# Video_Encoder register map
Vendor: Texas Instruments
Peripheral module from a debugger description file (folder omap36xx).
Registers are 32-bit, read-write, reset 0x0 unless marked. A register's access mark holds for its fields unless they carry their own. Offsets are as the file gives them; lines under a group give offsets from that group; [hi:lo] are bit positions; {n}, {i} and the like mark numbered series; 'fields as' and 'values as' point back to an identical list; <NAME> marks a mode.

## Video_Encoder
0x00 VENC_REV_ID ro (reset mask 0xFFFFFF00) — Revision ID for the encoder
  [7:0] REV_ID — This read-only register contains the revision ID for the encoder. The revision ID will identify different revisions of the IP.
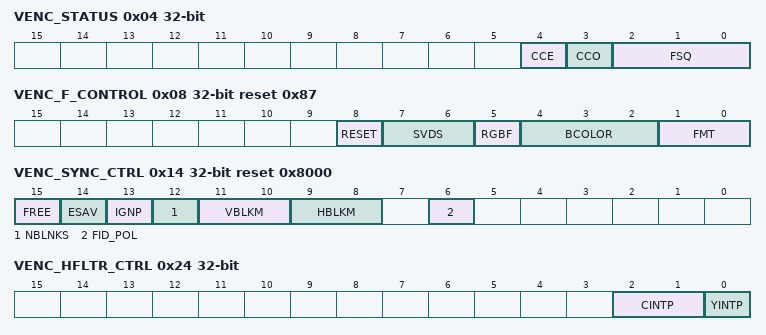
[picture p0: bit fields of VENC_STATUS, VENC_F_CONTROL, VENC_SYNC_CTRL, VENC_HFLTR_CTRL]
0x04 VENC_STATUS ro
  [4] CCE — Closed caption status for even Field.This bit is set immediately after the data in registers LINE21_E0 and LINE21_E1 have been encoded to closed caption. This bit is reset when both of these registers are written.
  [3] CCO — Closed Caption Status for Odd Field.This bit is set immediately after the data in registers LINE21_O0 and LINE21_O1 have been encoded to closed caption. This bit is reset when both of these registers are written.
  [2:0] FSQ — Field Sequence ID.For PAL, all three FSQ[2:0] are used whereas for NTSC only FSQ[1:0] is meaningful. Furthermore, FSQ[0] represents odd field when it is 0 and even field when it is 1.
    0=FSQ_0_r (Odd field); 1=FSQ_1_r (Even field)
0x08 VENC_F_CONTROL reset 0x87 — This register specifies the input video source and format
  [8] RESET — RESET the encoder
    0=No effect; 1=Reset the encoder, after reset, this bit is automatically set to zero
  [7:6] SVDS — Select Video Data Source.
    0=Use external video source; 1=Use internal Color BAR; 2=Use background color
  [5] RGBF — RGB/YCrCb input coding range
    0=The input RGB data are in binary format with coding range 0-255The input YCrCb data are in binary format with coding range 0-255; 1=The input RGB data are in binary format with coding range 16-235The input YCrCb data are in binary format conforming to ITU-601 standard
  [4:2] BCOLOR — Background color select
    0=black; 1=blue; 2=red; 3=magenta; 4=green; 5=cyan; 6=yellow; 7=white
  [1:0] FMT — These two bits specify the video input data stream format and timing
    0=24-bit 4:4:4 RGB; 1=24-bit 4:4:4; 2=16-bit 4:2:2; 3=8-bit ITU-R 656 4:2:2
0x10 VENC_VIDOUT_CTRL — Encoder output clock
  [0] _27_54
    0=27_54_0 (54 MHz, 4x oversampling); 1=27_54_1 (27 MHz, 2x oversampling, the last 2x oversampling filter bypassed)
0x14 VENC_SYNC_CTRL reset 0x8000 — Sync Control Register
  [15] FREE — Free running
    0=Free running disabled; 1=Free running enabled. HSYNC and VSYNC are ignored
  [14] ESAV — Enable to detect F and V bits only on EAV in ITU-R 656 input mode
    0=Detection of F and V bits on both EAV and SAV; 1=Detection of F and V bits only on EAV
  [13] IGNP — Ignore protection bits in ITU-R 656 input mode
    0=Protection bits are not ignored; 1=Protection bits are ignored
  [12] NBLNKS — Blank shaping
    0=Blank shaping enabled; 1=Blank shaping disabled
  [11:10] VBLKM — Vertical blanking mode
    0=Internal default blanking; 1=Internal default blanking AND internal programmable blanking defined by[24:16]FAL and [8:0] LAL bit fields. Note: in this mode, the [16] SBLANK bit must be '0b1' to active the VBLKM functionality.
  [9:8] HBLKM — Horizontal blanking mode
    0=Internal default blanking; 1=Internal programmable blanking defined by[26:16] SAVID and [10:0] EAVID bit fields; 2=External blanking defined by and registers
  [6] FID_POL — FID output polarity
    0=Odd field = 0Even field = 1; 1=Odd field = 1Even field = 0
0x1C VENC_LLEN reset 0x359
  [10:0] LLEN — LLEN[10:0]Line length or total number of pixels in a scan line including active video and blanking. Total number of pixels in a scan line = LLEN A write on the LLEN[10] is illegal.
0x20 VENC_FLENS reset 0x20C
  [10:0] FLENS — The frame length or total number of lines in a frame including active video and blanking from the source image.Total number of lines in a frame from the source image = FLENS + 1
0x24 VENC_HFLTR_CTRL
  [2:1] CINTP — Chrominance interpolation filter control
    0=The chrominance interpolation filter is enabled; 1=The first section of the chrominance interpolation filter is bypassed; 2=The second section of the chrominance interpolation filter is bypassed; 3=Both sections of the filter are bypassed
  [0] YINTP — Luminance interpolation filter control
    0=The luminance interpolation filter is enabled; 1=The luminance interpolation filter is bypassed
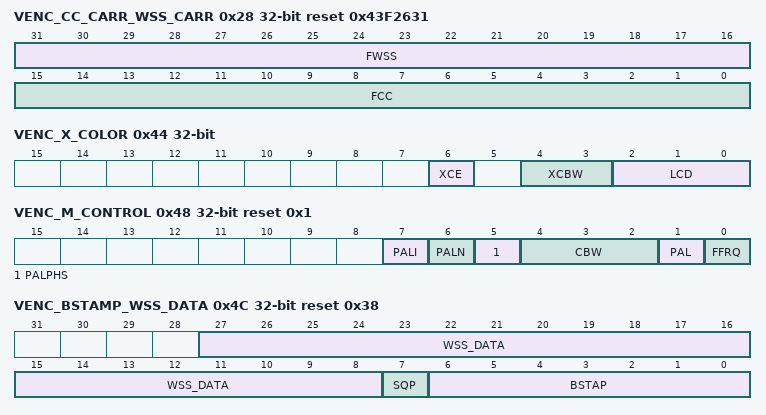
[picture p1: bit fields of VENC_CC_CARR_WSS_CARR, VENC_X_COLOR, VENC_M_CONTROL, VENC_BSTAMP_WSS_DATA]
0x28 VENC_CC_CARR_WSS_CARR reset 0x43F2631 — Frequency code control
  [31:16] FWSS — Wide screen signaling run-in code frequency controlFor common values for FWSS[15:0] bit field, refer to Reset value is for NTSC-601standard
  [15:0] FCC — Close caption run-in code frequency controlFor common values for FCC[15:0] bit field refer to . Reset value is for NTSC-601 standard
0x2C VENC_C_PHASE
  [7:0] CPHS — Phase of the encoded video color subcarrier (including the color burst) relative to H-sync. The adjustable step is 360/256 degrees.
0x30 VENC_GAIN_U reset 0x102 — Gain control for Cb signal
  [8:0] GU — Gain control for Cb signal. Following are typical programming examples for NTSC and PAL standards. NTSC with 7.5 IRE pedestal: WHITE - BLACK = 92.5 IRE GU = 0x102 NTSC with no pedestal: WHITE - BLACK = 100 IRE GU = 0x117PAL with no pedestal: WHITE - BLACK = 100 IRE GU = 0x111
0x34 VENC_GAIN_V reset 0x16C — Gain control of Cr signal
  [8:0] GV — Gain control of Cr signal. Following are typical programming examples for NTSC and PAL standards. NTSC with 7.5 IRE pedestal: WHITE - BLACK = 92.5 IRE GV = 0x16CNTSC with no pedestal: WHITE - BLACK = 100 IRE GV = 0x189PAL with no pedestal: WHITE - BLACK = 100 IRE GV = 0x181
0x38 VENC_GAIN_Y reset 0x12F — Gain control of Y signal
  [8:0] GY — Gain control of Y signal. Following are typical programming examples for NTSC/PAL standards.NTSC with 7.5 IRE pedestal: WHITE - BLACK = 92.5 IRE GY = 0x12FNTSC with no pedestal: WHITE - BLACK = 100 IRE GY = 0x147PAL with no pedestal: WHITE - BLACK = 100 IRE GY = 0x140
0x3C VENC_BLACK_LEVEL reset 0x43 — Video Encoder BLACK LEVEL
  [6:0] BLACK — Black level setting. Following are typical programming examples for NTSC/PAL standards. NTSC with 7.5 IRE pedestal: WHITE - BLACK = 92.5 IRE BLACK_LEVEL = 0x43 NTSC with no pedestal: WHITE - BLACK = 100 IRE BLACK_LEVEL = 0x38PAL with no pedestal: WHITE - BLACK = 100 IRE BLACK_LEVEL = 0x3B
0x40 VENC_BLANK_LEVEL reset 0x38 — Video Encoder BLANK LEVEL
  [6:0] BLANK — Blank level setting. Following are typical programming examples for NTSC/PAL standards. NTSC with 7.5 IRE pedestal: WHITE - BLACK = 92.5 IRE BLANK_LEVEL = 0x38NTSC with no pedestal: WHITE - BLACK = 100 IRE BLANK_LEVEL = 0x38PAL with no pedestal: WHITE - BLACK = 100 IRE BLANK_LEVEL = 0x3B
0x44 VENC_X_COLOR — Cross-Color Control Register
  [6] XCE — Cross color reduction enable for composite video output. Cross color does not affect S-video output
    0=Cross color reduction is disabled; 1=Cross color is enabled
  [4:3] XCBW — Cross color reduction filter selection
    0=The notch is at 32.8 % of the frequency of the encoding pixel clock; 1=The notch is at 26.5 % of the frequency of the encoding pixel clock; 2=The notch is at 30.0 % of the frequency of the encoding pixel clock; 3=The notch is at 29.2 % of the frequency of the encoding pixel clock
  [2:0] LCD — These three bits can be used for chroma channel delay compensation. Delay on Luma channel.
    0=0; 1=0.5 pixel clock period; 2=1.0 pixel clock period; 3=1.5 pixel clock period; 4=-2.0 pixel clock period; 5=-1.5 pixel clock period; 6=-1.0 pixel clock period; 7=-0.5 pixel clock period
0x48 VENC_M_CONTROL reset 0x1
  [7] PALI — PAL I enable
    0=Normal operation; 1=PAL I enable
  [6] PALN — PAL N enable
    0=Normal operation; 1=PAL N enable
  [5] PALPHS — PAL switch phase setting
    0=PAL switch phase is nominal; 1=PAL switch phase is inverted compared to nominal
  [4:2] CBW — Chrominance lowpass filter bandwidth control
    0=-6db at 21.8 % of encoding pixel clock frequency; 1=-6db at 19.8 % of encoding pixel clock frequency; 2=-6db at 18.0 % of encoding pixel clock frequency; 5=-6db at 23.7 % of encoding pixel clock frequency; 6=-6db at 26.8 % of encoding pixel clock frequency; 7=Chrominance lowpass filter bypass
  [1] PAL — Phase alternation line encoding selection
    0=Phase alternation line encoding disabled; 1=Phase alternation line encoding enabled
  [0] FFRQ — The value of this field and the SQP bit in theVENC_BSTAMP_WSS_DATA[7] SQP bit control the number of horizontal pixels displayed per scan lineMode: Configuration: . ITU-R 601 NTSC SQP = 0, FFRQ = 1, Number of pixels by line = 858 . Square pixel NTSC SQP = 1, FFRQ = 1, Number of pixels by line = 780 . ITU-R 601 PAL SQP = 0, FFRQ = 0, Number of pixels by line = 864 . Square pixel PAL SQP = 1, FFRQ = 0, Number of pixels by line = 944 .
0x4C VENC_BSTAMP_WSS_DATA reset 0x38 — VENC BSTAMP and WSS_DATA
  [27:8] WSS_DATA — WSS data [19:0]: Wide Screen Signaling dataNTSC: WORD 0 WSS_D1, WSS_D0 . WORD 1 WSS_D5, WSS_D4, WSS_D3, WSS_D2 . WORD 2 WSS_D13, WSS_D12, WSS_D11, WSS_D10, WSS_D9, WSS_D8, WSS_D7, WSS_D6 . CRC WSS_D19, WSS_D18, WSS_D17, WSS_D16, WSS_D15, WSS_D14 . PAL: GROUP A WSS_D3, WSS_D2, WSS_D1, WSS_D0 . GROUP B WSS_D7, WSS_D6, WSS_D5, WSS_D4 . GROUP C WSS_D10, WSS_D9, WSS_D8 . GROUP D WSS_D13, WSS_D12, WSS_D11 .
  [7] SQP — Square-pixel sampling rate. Please refer toVENC_M_CONTROL[0] FFRQ bit description for programming information.
    0=ITU-R 601 sampling rate; 1=Square-pixel sampling rate
  [6:0] BSTAP — Setting of amplitude of color burst.
0x50 VENC_S_CARR reset 0x21F07C1F — Color Subcarrier Frequency Registers.
  [31:0] FSC — These four bytes' data program the color subcarrier frequency and are determined by the following formula.S_CARR = ROUND((Fsc/Fclkenc) * 2)Where: Fsc = Frequency of the subcarrierFclkenc = Frequency of the internal video encoding clock = 2*LLEN *FhLLEN = Number of pixels in a scan line. For LLEN setting, please refer to the description of VENC_LLEN register (offset 0x1C).Fh = Line frequencyFor typical setting of the FSC field, refer to .
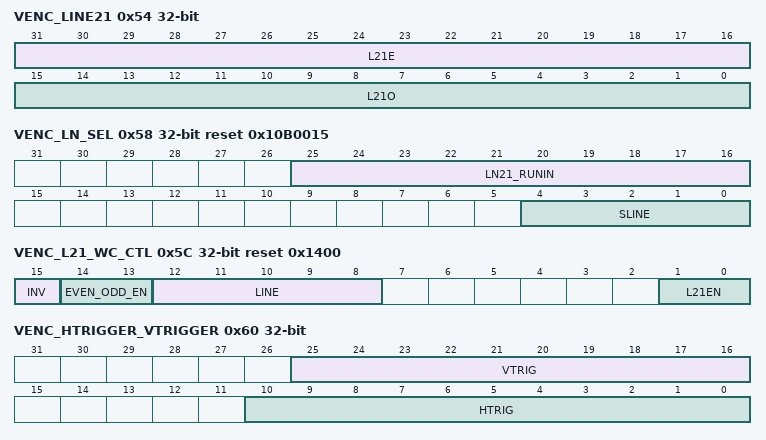
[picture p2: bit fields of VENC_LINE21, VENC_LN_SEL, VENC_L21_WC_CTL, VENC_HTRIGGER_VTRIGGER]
0x54 VENC_LINE21
  [31:16] L21E — The two bytes of the closed-caption data in the even field. For a complete field description, refer to CEA-608-x standard. For data stream content, see, .[31:24] First byte of data . [23:16] Second byte of data .
  [15:0] L21O — The two bytes of the closed caption data in the odd field. For a complete field description, refer to CEA-608-x standard. For data stream content, see, .[15:8] First byte of data . [7:0] Second byte of data .
0x58 VENC_LN_SEL reset 0x10B0015
  [25:16] LN21_RUNIN — The two bytes of the closed caption run in code position from the HSYNC.
  [4:0] SLINE — Selects the line where closed caption or extended service data are encoded. The value of the SLINE[4:0] bit field depends on the video standard:PAL mode: Because there is a one-line offset, program the desired line number – 1. . To activate the closed caption on line 21 (0x15), program the value 0x15 – 1 = 0x14. The default value is 0x15 + 1 = 0x16 (line 22). . NTSC mode: Because there is a four-line offset, program the desired line number – 4. . To activate the closed caption on line 21 (0x15), program the value 0x15 – 4 = 0x11. The default value is 0x15 + 4 = 0x19 (line 25). .
0x5C VENC_L21_WC_CTL reset 0x1400 — VENC L21 WC_CTL registers
  [15] INV — WSS inverter
    0=No effect; 1=Invert WSS data
  [14:13] EVEN_ODD_EN — This bit controls the WSS encoding.
    0=WSS encoding OFF; 1=Enables encoding in 1st field (odd field); 2=Enables encoding in 2nd field (even field); 3=Enables encoding in both fields
  [12:8] LINE — Selects the line where WSS data are encoded. The LINE[12:8] bit field value depends on the video standard:PAL mode: There is an one line offset, so program the wanted line number - 1. The recommended value is line 0x16 + 1 = 0x17 (23rd line). The default value is 0x14 + 1 = 0x15 (line 21).NTSC mode: There is a four line offset, so program the wanted line number - 4. The recommended value is line 0x10 + 4 = 0x14 (20th line). The default value is 0x14 + 4 = 0x18 (line 24).
  [1:0] L21EN — Those bits controls the Line21 closed caption encoding according to the mode.
    0=Line21 encoding OFF; 1=Enables encoding in 1st field (odd field); 2=Enables encoding in 2d field (even field); 3=Enables encoding in both fields
0x60 VENC_HTRIGGER_VTRIGGER — VENC HTRIGGER and VTRIGGER
  [25:16] VTRIG — Vertical trigger reference for VSYNC. These bits specify the phase between VSYNC input and the lines in a field. The VTRIG field is expressed in units of half-line.
  [10:0] HTRIG — Horizontal trigger phase, which sets HSYNC. HTRIG is expressed in half-pixels or clk2x (27 MHz) periods
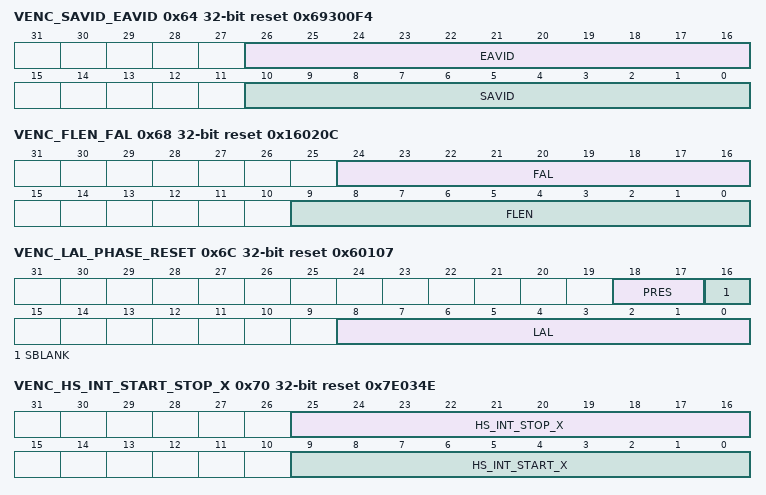
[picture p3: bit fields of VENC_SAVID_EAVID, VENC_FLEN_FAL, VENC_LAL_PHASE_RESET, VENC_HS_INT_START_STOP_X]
0x64 VENC_SAVID_EAVID reset 0x69300F4 — VENC SAVID and EAVID
  [26:16] EAVID — End of active video. These bits define the ending pixel position on a horizontal display line where active video will be displayed.
  [10:0] SAVID — Start of active video. These bits define the starting pixel position on a horizontal line where active video will be displayed.
0x68 VENC_FLEN_FAL reset 0x16020C — VENC FLEN and FAL
  [24:16] FAL — First Active Line of Field. These bits define the first active line of a field
  [9:0] FLEN — Field length. These bits define the number of half_lines in each field.Length of field = (FLEN + 1) half_lines
0x6C VENC_LAL_PHASE_RESET reset 0x60107 — VENC LAL and PHASE_RESET
  [18:17] PRES — Phase reset mode.
    0=No reset; 1=Reset every two lines; 2=Reset every eight fields. Color subcarrier phase is reset to VENC_CPHASE[7:0] CPHS field value (offset 0x2C) upon reset; 3=Reset every four fields. Color subcarrier phase is reset to VENC_CPHASE[7:0] CPHS bit field value (offset 0x2C) upon reset
  [16] SBLANK — Data output enable
    0=No functionality; 1=Enables the output of data when[10] VBLMK bit is '0b1'
  [8:0] LAL — Last Active Line of Field. These bits define the last active line of a field. The LAL[8:0] bit field value must be set to a value lower than the active window.
0x70 VENC_HS_INT_START_STOP_X reset 0x7E034E
  [25:16] HS_INT_STOP_X — HSYNC internal stop. These bits define HSYNC internal stop pixel value
  [9:0] HS_INT_START_X — HSYNC internal start. These bits define HSYNCI NTERNAL start pixel value
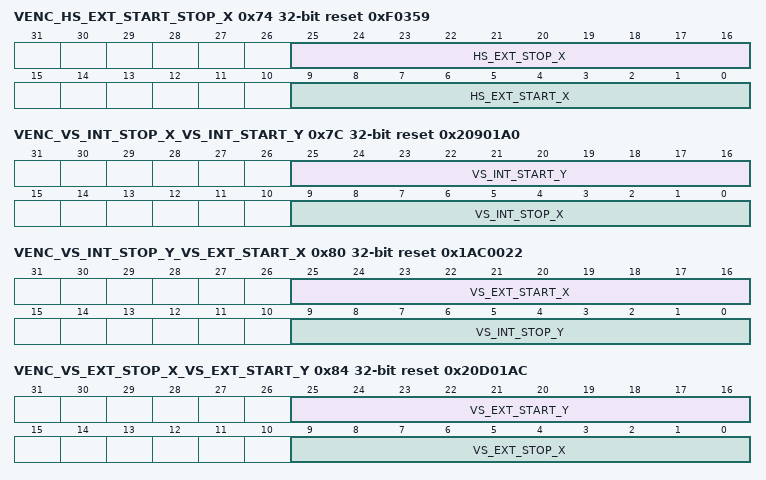
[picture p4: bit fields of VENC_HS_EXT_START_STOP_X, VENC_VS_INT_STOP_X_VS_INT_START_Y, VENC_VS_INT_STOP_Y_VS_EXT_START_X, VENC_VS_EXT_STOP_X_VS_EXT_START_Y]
0x74 VENC_HS_EXT_START_STOP_X reset 0xF0359
  [25:16] HS_EXT_STOP_X — HSYNC external stop. These bits define HSYNC external stop pixel value
  [9:0] HS_EXT_START_X — HSYNC external start. These bits define HSYNC EXTERNAL start pixel value
0x78 VENC_VS_INT_START_X reset 0x1A00000
  [25:16] VS_INT_START_X — VSYNC internal start. These bits define VSYNC internal start pixel value.
0x7C VENC_VS_INT_STOP_X_VS_INT_START_Y reset 0x20901A0 — VENC VS_INT_STOP_X and VS_INT_START_Y
  [25:16] VS_INT_START_Y — VSYNC internal start. These bits define VSYNC INTERNAL start line value
  [9:0] VS_INT_STOP_X — VSYNC internal stop. These bits define VSYNC internal stop pixel value
0x80 VENC_VS_INT_STOP_Y_VS_EXT_START_X reset 0x1AC0022 — VENC VS_INT_STOP_Y and VS_EXT_START_X
  [25:16] VS_EXT_START_X — VSYNC external start. These bits define VSYNC external start pixel value.
  [9:0] VS_INT_STOP_Y — VSYNC internal stop. These bits define VSYNC INTERNAL stop line value.
0x84 VENC_VS_EXT_STOP_X_VS_EXT_START_Y reset 0x20D01AC — VENC VS_EXT_STOP_X and VS_EXT_START_Y
  [25:16] VS_EXT_START_Y — VSYNC external start. These bits define VSYNC EXTERNAL start line value.
  [9:0] VS_EXT_STOP_X — VSYNC external stop. These bits define VSYNC EXTERNAL stop pixel value.
0x88 VENC_VS_EXT_STOP_Y reset 0x6
  [9:0] VS_EXT_STOP_Y — VSYNC external stop. These bits define VSYNC EXTERNAL stop line value.
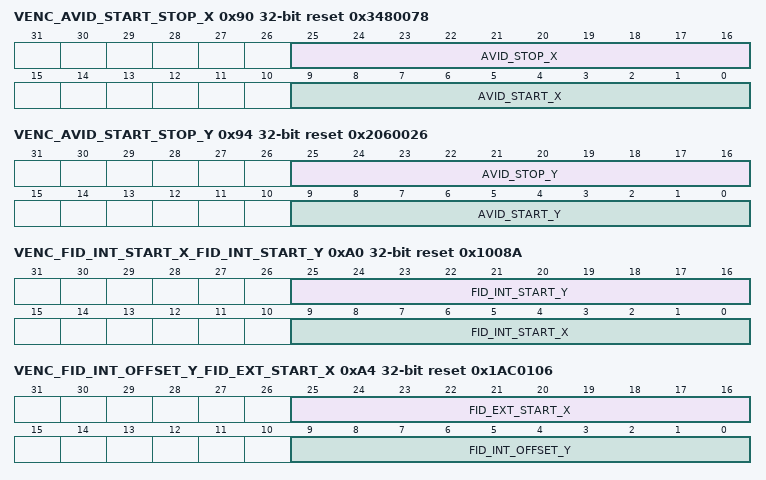
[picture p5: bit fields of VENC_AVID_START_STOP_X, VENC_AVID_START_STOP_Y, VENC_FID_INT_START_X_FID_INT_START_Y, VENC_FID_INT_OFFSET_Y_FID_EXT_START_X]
0x90 VENC_AVID_START_STOP_X reset 0x3480078
  [25:16] AVID_STOP_X — AVID stop. These bits define AVID stop pixel value
  [9:0] AVID_START_X — AVID start. These bits define AVID start pixel value
0x94 VENC_AVID_START_STOP_Y reset 0x2060026
  [25:16] AVID_STOP_Y — AVID stop. These bits define AVID stop line value.
  [9:0] AVID_START_Y — AVID start. These bits define AVID start line value
0xA0 VENC_FID_INT_START_X_FID_INT_START_Y reset 0x1008A — VENC_FID_INT_START_X and FID_INT_START_Y
  [25:16] FID_INT_START_Y — FID internal start. These bits define FID internal start line value
  [9:0] FID_INT_START_X — FID internal start. These bits define FID internal start pixel value
0xA4 VENC_FID_INT_OFFSET_Y_FID_EXT_START_X reset 0x1AC0106 — VENC FID_INT_OFFSET_Y and FID_EXT_START_X
  [25:16] FID_EXT_START_X — FID external start. These bits define FID external start pixel value
  [9:0] FID_INT_OFFSET_Y — FID internal offset. These bits define FID internal offset linel value
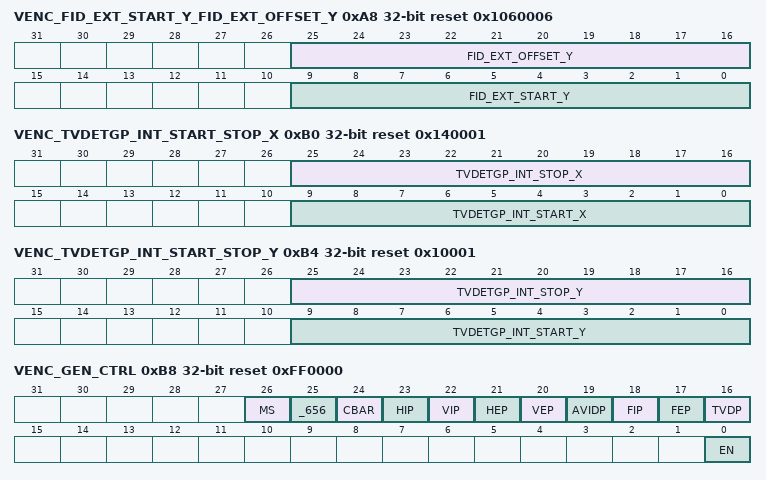
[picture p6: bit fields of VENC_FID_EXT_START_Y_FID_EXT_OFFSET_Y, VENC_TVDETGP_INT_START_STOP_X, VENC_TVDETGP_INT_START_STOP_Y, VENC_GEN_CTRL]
0xA8 VENC_FID_EXT_START_Y_FID_EXT_OFFSET_Y reset 0x1060006 — VENC FID_EXT_START_Y and FID_EXT_OFFSET_Y
  [25:16] FID_EXT_OFFSET_Y — FID external offset. These bits define FID external offset line value
  [9:0] FID_EXT_START_Y — FID external start. These bits define FID external start line value.
0xB0 VENC_TVDETGP_INT_START_STOP_X reset 0x140001 — TV Detection Start and Stop pixel values
  [25:16] TVDETGP_INT_STOP_X — TVDETGP internal stop. These bits define TVDETGP internal stop pixel value.
  [9:0] TVDETGP_INT_START_X — TVDETGP internal start. These bits define TVDETGP internal start pixel value
0xB4 VENC_TVDETGP_INT_START_STOP_Y reset 0x10001 — TV detection Start and Stop line values
  [25:16] TVDETGP_INT_STOP_Y — TVDETGP internal stop. These bits define TVDETGP internal stop line value.
  [9:0] TVDETGP_INT_START_Y — TVDETGP internal start. These bits define TVDETGP internal start line value.
0xB8 VENC_GEN_CTRL reset 0xFF0000 — TVDETGP enable and SYNC_POLARITY and UVPHASE_POL
  [26] MS — UVPHASE_POL MS mode UV phase
    0=CbCr; 1=CrCb
  [25] _656 — UVPHASE_POL 656 input mode UV phase
    0=656_0 (CbCr); 1=656_1 (CrCb)
  [24] CBAR — UVPHASE_POL CBAR mode UV phase
    0=CbCr; 1=CrCb
  [23] HIP — HSYNC internal polarity
    0=Active low; 1=Active high
  [22] VIP — VSYNC internal polarity
    0=Active low; 1=Active high
  [21] HEP — HSYNC external polarity
    0=Active low; 1=Active high
  [20] VEP — VSYNC external polarity
    0=Active low; 1=Active high
  [19] AVIDP — AVID polarity
    0=Active low; 1=Active high
  [18] FIP — FID internal polarity
    0=Active low; 1=Active high
  [17] FEP — FID external polarity
    0=Active low; 1=Active high
  [16] TVDP — TVDETGP polarity
    0=Active low; 1=Active high
  [0] EN — TVDETGP generation enable
    0=Disabled; 1=Enabled
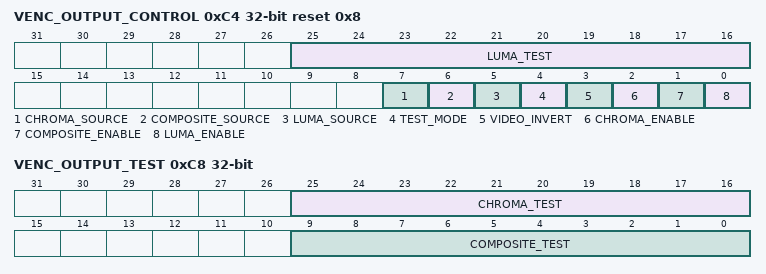
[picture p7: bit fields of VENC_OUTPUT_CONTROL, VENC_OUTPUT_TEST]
0xC4 VENC_OUTPUT_CONTROL reset 0x8 — Output channel control register Also contains some test control features
  [25:16] LUMA_TEST — In test mode, DAC 1 input value(if s-video video mode is selected)
  [7] CHROMA_SOURCE — Source of chroma video data in test mode
    0=Chroma test data comes from internal register OUTPUT_TEST[25:16]; 1=Chroma test data comes from display controller video port G[1:0], B[7:0]
  [6] COMPOSITE_SOURCE — Source of composite video data in test mode
    0=Composite test data comes from internal register OUTPUT_TEST[9:0]; 1=Composite test data comes from display controller video port G[1:0], B[7:0]
  [5] LUMA_SOURCE — Source of luminance video data in test mode
    0=Luma test data comes from internal register OUTPUT_CONTROL[25:16]; 1=Luma test data comes from display controller video port G[1:0], B[7:0]
  [4] TEST_MODE — This enables the video DACs to be tested. The values sent to the DACs comes from a register for each output channel (Luma, Composite or Chroma) or from the display controller video port bits G[1:0], B[7:0], depending on the setting of the Source bits
    0=Video outputs are in normal operation; 1=Test mode. Video outputs are directly connected to either internal registers or the display controller video port.
  [3] VIDEO_INVERT — Controls the video output polarity. This may be used to correct for inversion in an external video amplifier.
    0=Video outputs are inverted; 1=Video outputs are normal polarity
  [2] CHROMA_ENABLE — Enable the Chrominance output channel
    0=Chroma output is disabled; 1=Chroma output is enabled
  [1] COMPOSITE_ENABLE — Enable the Composite output channel
    0=Composite output is disabled; 1=Composite output is enabled
  [0] LUMA_ENABLE — Enable the Luminance output channel
    0=Luma output is disabled; 1=Luma output is enabled
0xC8 VENC_OUTPUT_TEST — Test values for the Luma/Composite Video DAC1 (if composite video is selected) and the Chroma Video DAC2
  [25:16] CHROMA_TEST — In test mode, DAC 2 input value
  [9:0] COMPOSITE_TEST — In test mode, DAC 1 input value (if composite video is selected)
